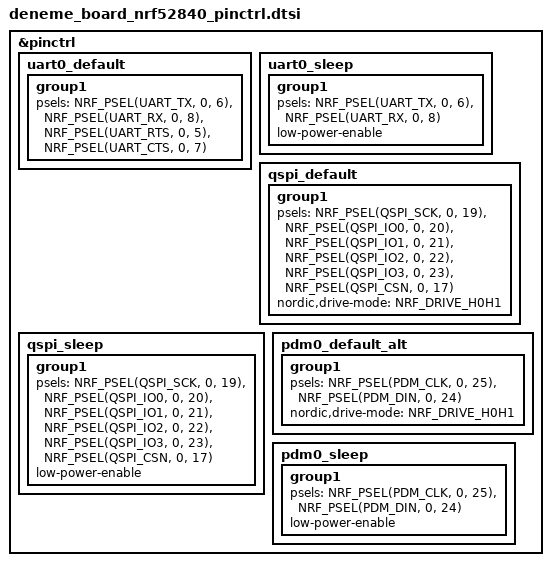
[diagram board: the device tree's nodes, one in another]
/*
 * Copyright (c) 2025 Your Company
 * SPDX-License-Identifier: Apache-2.0
 */

&pinctrl {
    /* UART0 NFC pins, can be used as GPIO or UART */
    uart0_default: uart0_default {
        group1 {
            psels = <NRF_PSEL(UART_TX, 0, 6)>,
                    <NRF_PSEL(UART_RX, 0, 8)>,
                    <NRF_PSEL(UART_RTS, 0, 5)>,
                    <NRF_PSEL(UART_CTS, 0, 7)>;
        };
    };

    uart0_sleep: uart0_sleep {
        group1 {
            psels = <NRF_PSEL(UART_TX, 0, 6)>,
                    <NRF_PSEL(UART_RX, 0, 8)>;
            low-power-enable;
        };
    };

    /* QSPI pins configuration */
    qspi_default: qspi_default {
        group1 {
            psels = <NRF_PSEL(QSPI_SCK, 0, 19)>,
                    <NRF_PSEL(QSPI_IO0, 0, 20)>,
                    <NRF_PSEL(QSPI_IO1, 0, 21)>,
                    <NRF_PSEL(QSPI_IO2, 0, 22)>,
                    <NRF_PSEL(QSPI_IO3, 0, 23)>,
                    <NRF_PSEL(QSPI_CSN, 0, 17)>;
            nordic,drive-mode = <NRF_DRIVE_H0H1>;
        };
    };

    qspi_sleep: qspi_sleep {
        group1 {
            psels = <NRF_PSEL(QSPI_SCK, 0, 19)>,
                    <NRF_PSEL(QSPI_IO0, 0, 20)>,
                    <NRF_PSEL(QSPI_IO1, 0, 21)>,
                    <NRF_PSEL(QSPI_IO2, 0, 22)>,
                    <NRF_PSEL(QSPI_IO3, 0, 23)>,
                    <NRF_PSEL(QSPI_CSN, 0, 17)>;
            low-power-enable;
        };
    };

    /* PDM microphone interface */
    pdm0_default_alt: pdm0_default_alt {
        group1 {
            psels = <NRF_PSEL(PDM_CLK, 0, 25)>,
                    <NRF_PSEL(PDM_DIN, 0, 24)>;
            nordic,drive-mode = <NRF_DRIVE_H0H1>;
        };
    };

    pdm0_sleep: pdm0_sleep {
        group1 {
            psels = <NRF_PSEL(PDM_CLK, 0, 25)>,
                    <NRF_PSEL(PDM_DIN, 0, 24)>;
            low-power-enable;
        };
    };
};
